AUTOSAR XML (schema 4-0-3)
package /ComponentTypes
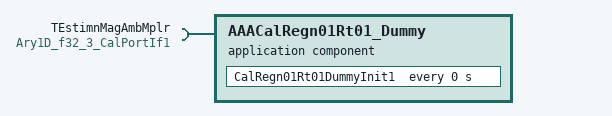
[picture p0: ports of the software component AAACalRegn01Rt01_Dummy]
  application sw component type AAACalRegn01Rt01_Dummy
    require port TEstimnMagAmbMplr: parameter-require-com-spec{init-value=[0.01, 0.01, 0.01], parameter=Ary1D}, required-interface=Ary1D_f32_3_CalPortIf1
    behavior AAACalRegn01Rt01_Dummy_InternalBehavior: supports-multiple-instantiation=true
      timing event AAACalRegn01Rt01_Dummy_InitEvent: start-on-event=CalRegn01Rt01DummyInit1, period=0
      runnable CalRegn01Rt01DummyInit1
  swc implementation AAACalRegn01Rt00_Dummy_Implementation: behavior=AAACalRegn01Rt01_Dummy_InternalBehavior
    code-descriptors:
      code Default: artifact-descriptors=autosar-engineering-object={short-label=Default, category=SWSRC}
